# RP2350 register map
Vendor: Raspberry Pi; Series: RP; File version: 0.1
CPU: CM33 r1p0, little endian, MPU, FPU, DSP, VTOR, 4 interrupt priority bits, 52 interrupts, 8 SAU regions
Registers are 32-bit, read-write, reset 0x0 unless marked. A register's access mark holds for its fields unless they carry their own. Offsets are from the block's base; [hi:lo] are bit positions; {n}, {i} and the like mark numbered series; 'fields as' and 'values as' point back to an identical list.

## CORESIGHT_TRACE — Coresight block - RP specific registers
Base 0x50700000
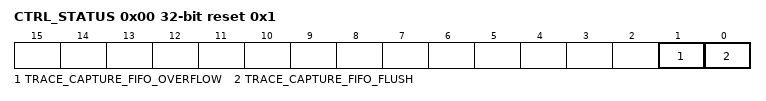
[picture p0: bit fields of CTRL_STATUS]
0x00 CTRL_STATUS reset 0x1 — Control and status register
  [1] TRACE_CAPTURE_FIFO_OVERFLOW — This status flag is set high when trace data has been dropped due to the FIFO being full at the point trace data was sampled. Write 1 to acknowledge and clear the bit.
  [0] TRACE_CAPTURE_FIFO_FLUSH — Set to 1 to continuously hold the trace FIFO in a flushed state and prevent overflow. Before clearing this flag, configure and start a DMA channel with the correct DREQ for the TRACE_CAPTURE_FIFO register. Clear this flag to begin sampling trace data, and set once again once the trace capture buffer is full. You must configure the TPIU in order to generate trace packets to be captured, as well as components like the ETM further upstream to generate the event stream propagated to the TPIU.
0x04 TRACE_CAPTURE_FIFO — FIFO for trace data captured from the TPIU
  [31:0] RDATA ro read-modifies — Read from an 8 x 32-bit FIFO containing trace data captured from the TPIU. Hardware pushes to the FIFO on rising edges of clk_sys, when either of the following is true: * TPIU TRACECTL output is low (normal trace data) * TPIU TRACETCL output is high, and TPIU TRACEDATA0 and TRACEDATA1 are both low (trigger packet) These conditions are in accordance with Arm Coresight Architecture Spec v3.0 section D3.3.3: Decoding requirements for Trace Capture Devices The data captured into the FIFO is the full 32-bit TRACEDATA bus output by the TPIU. Note that the TPIU is a DDR output at half of clk_sys, therefore this interface can capture the full 32-bit TPIU DDR output bandwidth as it samples once per active edge of the TPIU output clock.

## GLITCH_DETECTOR — Glitch detector controls
Base 0x40158000
0x00 ARM reset 0x5BAD — Forcibly arm the glitch detectors, if they are not already armed by OTP. When armed, any individual detector trigger will cause a restart of the switched core power domain's power-on reset state machine. Glitch detector triggers are recorded accumulatively in TRIG_STATUS. If the system is reset by a glitch detector trigger, this is recorded in POWMAN_CHIP_RESET. This register is Secure read/write only.
  [15:0] ARM
    0x5BAD=no (Do not force the glitch detectors to be armed); 0=yes (Force the glitch detectors to be armed. (Any value other than ARM_NO counts as YES))
0x04 DISARM
  [15:0] DISARM — Forcibly disarm the glitch detectors, if they are armed by OTP. Ignored if ARM is YES. This register is Secure read/write only.
    0=no (Do not disarm the glitch detectors. (Any value other than DISARM_YES counts as NO)); 0xDCAF=yes (Disarm the glitch detectors)
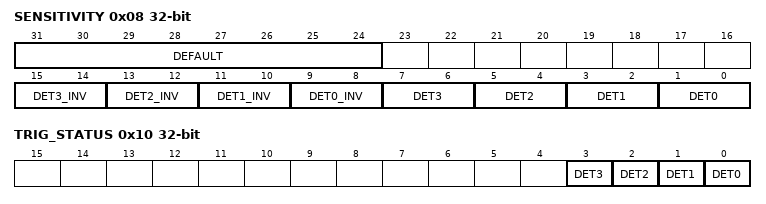
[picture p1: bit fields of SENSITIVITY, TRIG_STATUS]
0x08 SENSITIVITY — Adjust the sensitivity of glitch detectors to values other than their OTP-provided defaults. This register is Secure read/write only.
  [31:24] DEFAULT
    0=yes (Use the default sensitivity configured in OTP for all detectors. (Any value other than DEFAULT_NO counts as YES)); 222=no (Do not use the default sensitivity configured in OTP. Instead use the value from this register.)
  [2n+9:2n+8] DET{n}_INV (n=0..3) — Must be the inverse of DET{n}, else the default value is used.
  [2n+1:2n] DET{n} (n=0..3) — Set sensitivity for detector {n}. Higher values are more sensitive.
0x0C LOCK
  [7:0] LOCK — Write any nonzero value to disable writes to ARM, DISARM, SENSITIVITY and LOCK. This register is Secure read/write only.
0x10 TRIG_STATUS — Set when a detector output triggers. Write-1-clear. (May immediately return high if the detector remains in a failed state. Detectors can only be cleared by a full reset of the switched core power domain.) This register is Secure read/write only.
  [n] DET{n} write-1-clears (n=0..3)
0x14 TRIG_FORCE — Simulate the firing of one or more detectors. Writing ones to this register will set the matching bits in STATUS_TRIG. If the glitch detectors are currently armed, writing ones will also immediately reset the switched core power domain, and set the reset reason latches in POWMAN_CHIP_RESET to indicate a glitch detector resets. This register is Secure read/write only.
  [3:0] TRIG_FORCE wo

## TBMAN — For managing simulation testbenches
Base 0x40160000
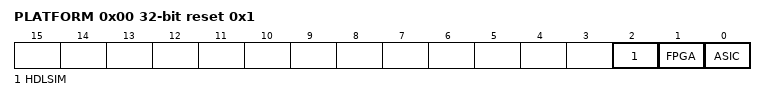
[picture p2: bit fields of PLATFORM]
0x00 PLATFORM reset 0x1 — Indicates the type of platform in use
  [2] HDLSIM ro — Indicates the platform is a simulation
  [1] FPGA ro — Indicates the platform is an FPGA
  [0] ASIC ro — Indicates the platform is an ASIC

## USB_DPRAM — DPRAM layout for USB device.
Base 0x50100000
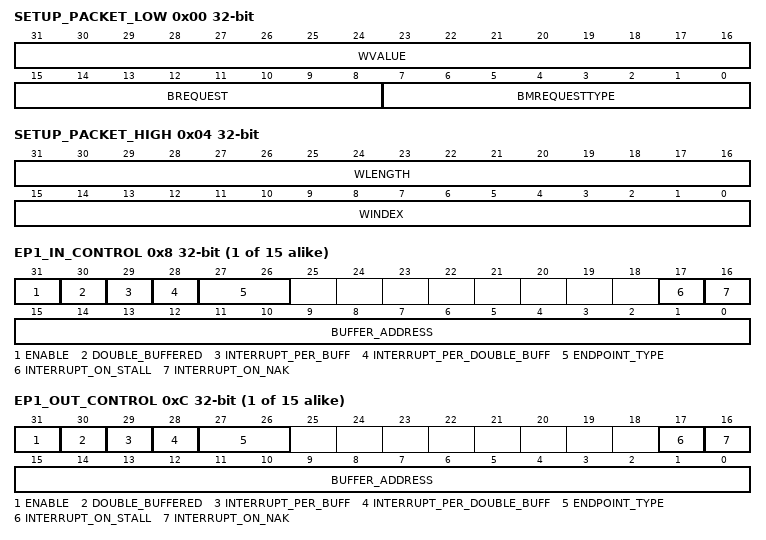
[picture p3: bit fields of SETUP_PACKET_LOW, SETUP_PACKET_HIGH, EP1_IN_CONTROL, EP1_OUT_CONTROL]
0x00 SETUP_PACKET_LOW — Bytes 0-3 of the SETUP packet from the host.
  [31:16] WVALUE, [15:8] BREQUEST, [7:0] BMREQUESTTYPE
0x04 SETUP_PACKET_HIGH — Bytes 4-7 of the setup packet from the host.
  [31:16] WLENGTH, [15:0] WINDEX
{0x0+8i} EP{i}_IN_CONTROL (i=1..15)
  [31] ENABLE — Enable this endpoint. The device will not reply to any packets for this endpoint if this bit is not set.
  [30] DOUBLE_BUFFERED — This endpoint is double buffered.
  [29] INTERRUPT_PER_BUFF — Trigger an interrupt each time a buffer is done.
  [28] INTERRUPT_PER_DOUBLE_BUFF — Trigger an interrupt each time both buffers are done. Only valid in double buffered mode.
  [27:26] ENDPOINT_TYPE
    0=Control; 1=Isochronous; 2=Bulk; 3=Interrupt
  [17] INTERRUPT_ON_STALL — Trigger an interrupt if a STALL is sent. Intended for debug only.
  [16] INTERRUPT_ON_NAK — Trigger an interrupt if a NAK is sent. Intended for debug only.
  [15:0] BUFFER_ADDRESS — 64 byte aligned buffer address for this EP (bits 0-5 are ignored). Relative to the start of the DPRAM.
{0x4+8i} EP{i}_OUT_CONTROL (i=1..15)
  fields as EP1_IN_CONTROL
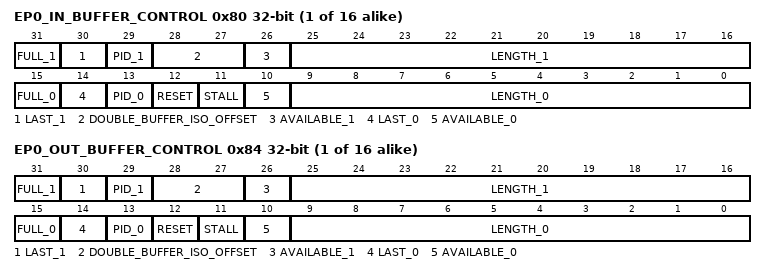
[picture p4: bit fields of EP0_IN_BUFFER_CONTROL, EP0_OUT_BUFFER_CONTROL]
{0x80+8i} EP{i}_IN_BUFFER_CONTROL (i=0..15) — Buffer control for both buffers of an endpoint. Fields ending in a _1 are for buffer 1. Fields ending in a _0 are for buffer 0. Buffer 1 controls are only valid if the endpoint is in double buffered mode.
  [31] FULL_1 — Buffer 1 is full. For an IN transfer (TX to the host) the bit is set to indicate the data is valid. For an OUT transfer (RX from the host) this bit should be left as a 0. The host will set it when it has filled the buffer with data.
  [30] LAST_1 — Buffer 1 is the last buffer of the transfer.
  [29] PID_1 — The data pid of buffer 1.
  [28:27] DOUBLE_BUFFER_ISO_OFFSET — The number of bytes buffer 1 is offset from buffer 0 in Isochronous mode. Only valid in double buffered mode for an Isochronous endpoint. For a non Isochronous endpoint the offset is always 64 bytes.
    0=128; 1=256; 2=512; 3=1024
  [26] AVAILABLE_1 — Buffer 1 is available. This bit is set to indicate the buffer can be used by the controller. The controller clears the available bit when writing the status back.
  [25:16] LENGTH_1 — The length of the data in buffer 1.
  [15] FULL_0 — Buffer 0 is full. For an IN transfer (TX to the host) the bit is set to indicate the data is valid. For an OUT transfer (RX from the host) this bit should be left as a 0. The host will set it when it has filled the buffer with data.
  [14] LAST_0 — Buffer 0 is the last buffer of the transfer.
  [13] PID_0 — The data pid of buffer 0.
  [12] RESET — Reset the buffer selector to buffer 0.
  [11] STALL — Reply with a stall (valid for both buffers).
  [10] AVAILABLE_0 — Buffer 0 is available. This bit is set to indicate the buffer can be used by the controller. The controller clears the available bit when writing the status back.
  [9:0] LENGTH_0 — The length of the data in buffer 1.
{0x84+8i} EP{i}_OUT_BUFFER_CONTROL (i=0..15) — Buffer control for both buffers of an endpoint. Fields ending in a _1 are for buffer 1. Fields ending in a _0 are for buffer 0. Buffer 1 controls are only valid if the endpoint is in double buffered mode.
  fields as EP0_IN_BUFFER_CONTROL
